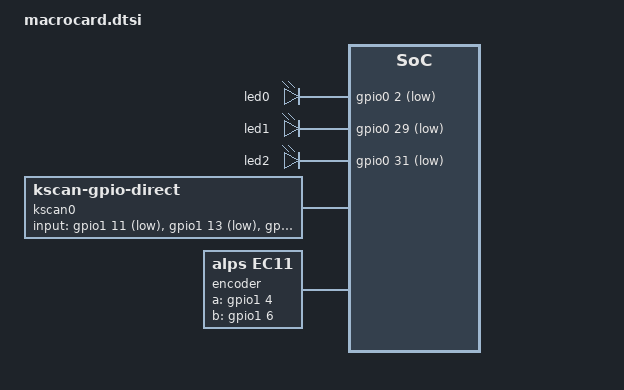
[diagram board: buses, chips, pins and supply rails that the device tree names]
#include <dt-bindings/zmk/matrix_transform.h>

/ {
    chosen {
        zmk,kscan = &kscan0;
        zmk,matrix_transform = &default_transform;
        // zmk,physical-layout = &physical_layout0;
    };

    aliases {
        led-red = &led0;
        led-green = &led1;
        led-blue = &led2;
    };

    leds {
        compatible = "gpio-leds";
        status = "okay";
        
        led0: led_0 {
            gpios = <&gpio0 2 GPIO_ACTIVE_LOW>;  // Red LED on P0.02
        };
        
        led1: led_1 {
            gpios = <&gpio0 29 GPIO_ACTIVE_LOW>;   // Green LED on P0.29
        };
        
        led2: led_2 {
            gpios = <&gpio0 31 GPIO_ACTIVE_LOW>;   // Blue LED on P0.31
        };
    };

    default_transform: keymap_transform_0 {
        compatible = "zmk,matrix-transform";
        columns = <4>;
        rows = <1>;
        map = <
            RC(0,0) RC(0,1) RC(0,2) RC(0,3)
        >;
    };

    // physical_layout0: physical_layout0 {
    //     compatible = "zmk,physical-layout";
    //     display-name = "Macrocard Layout";
        
    //     keys  //                     w   h    x    y     rot   rx   ry
    //         = <&key_physical_attrs 100 100    0    0       0    0    0>
    //         , <&key_physical_attrs 100 100  100    0       0    0    0>
    //         , <&key_physical_attrs 100 100  200    0       0    0    0>
    //         , <&key_physical_attrs 100 100  300    0       0    0    0>
    //         ;
    // };

    kscan0: kscan {
        compatible = "zmk,kscan-gpio-direct";
        wakeup-source;
        
        input-gpios = <&gpio1 11 (GPIO_ACTIVE_LOW | GPIO_PULL_UP)>,   // Switch 1 on P1.11
                      <&gpio1 13 (GPIO_ACTIVE_LOW | GPIO_PULL_UP)>,   // Switch 2 on P1.13
                      <&gpio1 15 (GPIO_ACTIVE_LOW | GPIO_PULL_UP)>,   // Switch 3 on P1.15
                      <&gpio0 24 (GPIO_ACTIVE_LOW | GPIO_PULL_UP)>;   // Encoder switch
    };

    encoder: encoder {
        compatible = "alps,ec11";
        a-gpios = <&gpio1 4 (GPIO_ACTIVE_HIGH | GPIO_PULL_UP)>;  // Pin A on P1.04
        b-gpios = <&gpio1 6 (GPIO_ACTIVE_HIGH | GPIO_PULL_UP)>;  // Pin B on P1.06
        steps = <80>;
        status = "okay";
    };
};

&encoder {
    status = "okay";
};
